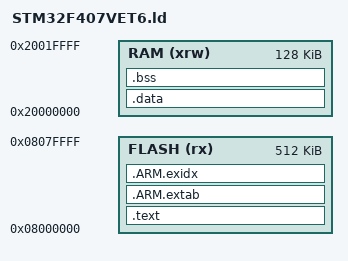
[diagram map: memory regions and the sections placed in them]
/*
 * STM32F407VET6 Linker Script
 * Now based on CMSIS 3.01 example
 */

__estack = 0x20020000;

MEMORY
{
  FLASH (rx) : ORIGIN = 0x08000000, LENGTH = 512K
  RAM (xrw)  : ORIGIN = 0x20000000, LENGTH = 128K
}

SECTIONS
{

  .text :
  {
    KEEP(*(vectors))
    *(.text*)

    KEEP(*(.init))
    KEEP(*(.fini))

    /* .ctors */
    *crtbegin.o(.ctors)
    *crtbegin?.o(.ctors)
    *(EXCLUDE_FILE(*crtend?.o *crtend.o) .ctors)
    *(SORT(.ctors.*))
    *(.ctors)

    /* .dtors */
    *crtbegin.o(.dtors)
    *crtbegin?.o(.dtors)
    *(EXCLUDE_FILE(*crtend?.o *crtend.o) .dtors)
    *(SORT(.dtors.*))
    *(.dtors)

    *(.rodata*)
    
    KEEP(*(.eh_frame*))
  } >FLASH

  .ARM.extab : 
  {
    *(.ARM.extab* .gnu.linkonce.armextab.*)
  } > FLASH

  __exidx_start = .;
  .ARM.exidx :
  {
    *(.ARM.exidx* .gnu.linkonce.armexidx.*)
  } > FLASH
  __exidx_end = .;

  __etext = .;

  .data : AT (__etext)
  {   
    __sdata = .;
    *(vtable)
    *(.data*)

    . = ALIGN(4);
    /* preinit data */
    PROVIDE_HIDDEN (__preinit_array_start = .);
    KEEP(*(.preinit_array))
    PROVIDE_HIDDEN (__preinit_array_end = .);

    . = ALIGN(4);
    /* init data */
    PROVIDE_HIDDEN (__init_array_start = .);
    KEEP(*(SORT(.init_array.*)))
    KEEP(*(.init_array))
    PROVIDE_HIDDEN (__init_array_end = .);

    . = ALIGN(4);
    /* finit data */
    PROVIDE_HIDDEN (__fini_array_start = .);
    KEEP(*(SORT(.fini_array.*)))
    KEEP(*(.fini_array))
    PROVIDE_HIDDEN (__fini_array_end = .);

    . = ALIGN(4);
    __edata = .;
  } > RAM

  .bss :
  {
    __sbss = .;
    *(.bss)
    __ebss = .;
  } > RAM

}

